# Special_Function_15 register map
Vendor: Texas Instruments
Peripheral module from a debugger description file (folder msp430).
Registers are 8-bit, read-write, reset 0x0 unless marked. A register's access mark holds for its fields unless they carry their own. Offsets are as the file gives them; lines under a group give offsets from that group; [hi:lo] are bit positions; {n}, {i} and the like mark numbered series; 'fields as' and 'values as' point back to an identical list; <NAME> marks a mode.

## Special_Function
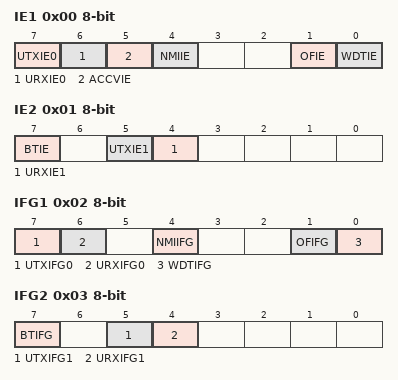
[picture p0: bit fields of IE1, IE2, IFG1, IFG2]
0x00 IE1 — Interrupt Enable 1
  [7] UTXIE0, [6] URXIE0, [5] ACCVIE, [4] NMIIE, [1] OFIE, [0] WDTIE
0x01 IE2 — Interrupt Enable 2
  [7] BTIE, [5] UTXIE1, [4] URXIE1
0x02 IFG1 — Interrupt Flag 1
  [7] UTXIFG0, [6] URXIFG0, [4] NMIIFG, [1] OFIFG, [0] WDTIFG
0x03 IFG2 — Interrupt Flag 2
  [7] BTIFG, [5] UTXIFG1, [4] URXIFG1
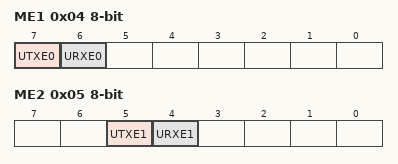
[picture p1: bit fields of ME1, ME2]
0x04 ME1 — Module Enable 1
  [7] UTXE0, [6] URXE0
0x05 ME2 — Module Enable 2
  [5] UTXE1, [4] URXE1
